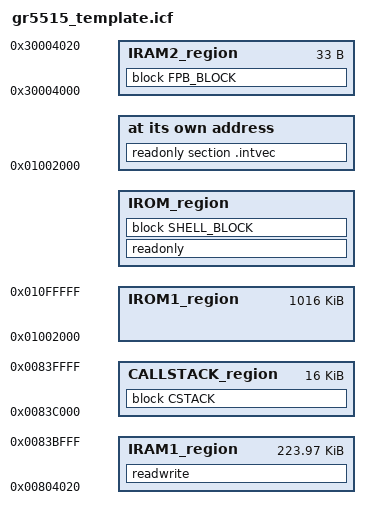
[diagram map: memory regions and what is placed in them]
/*###ICF### Section handled by ICF editor, don't touch! ****/
/*-Editor annotation file-*/
/* IcfEditorFile="$TOOLKIT_DIR$\config\ide\IcfEditor\cortex_v1_4.xml" */
/*-Specials-*/
define symbol __ICFEDIT_intvec_start__ = 0x01002000;
/*-Memory Regions-*/
define symbol __ICFEDIT_region_IROM1_start__ = 0x01002000;
define symbol __ICFEDIT_region_IROM1_end__   = 0x010FFFFF;
define symbol __ICFEDIT_region_IRAM1_start__ = 0x00804020;
define symbol __ICFEDIT_region_IRAM1_end__   = 0x0083BFFF;
define symbol __ICFEDIT_region_IRAM2_start__ = 0x30004000;
define symbol __ICFEDIT_region_IRAM2_end__   = 0x30004020;
define symbol __ICFEDIT_region_CALLSTACK_start__ = 0x0083C000;
define symbol __ICFEDIT_region_CALLSTACK_end__   = 0x0083FFFF;

/*-Sizes-*/
define symbol __ICFEDIT_size_cstack__     = 0x4000;
define symbol __ICFEDIT_size_proc_stack__ = 0x0;
define symbol __ICFEDIT_size_heap__       = 0x200;
/**** End of ICF editor section. ###ICF###*/

define memory mem with size = 4G;
define symbol use_IROM1 = (__ICFEDIT_region_IROM1_start__ != 0x0 || __ICFEDIT_region_IROM1_end__ != 0x0);
define symbol use_IRAM1 = (__ICFEDIT_region_IRAM1_start__ != 0x0 || __ICFEDIT_region_IRAM1_end__ != 0x0);
define symbol use_IRAM2 = (__ICFEDIT_region_IRAM2_start__ != 0x0 || __ICFEDIT_region_IRAM2_end__ != 0x0);


define region IROM1_region = mem:[from __ICFEDIT_region_IROM1_start__ to __ICFEDIT_region_IROM1_end__];

define region IROM_region = IROM1_region ;

define region IRAM1_region = mem:[from __ICFEDIT_region_IRAM1_start__ to __ICFEDIT_region_IRAM1_end__];

define region IRAM2_region = mem:[from __ICFEDIT_region_IRAM2_start__ to __ICFEDIT_region_IRAM2_end__];

define region CALLSTACK_region = mem:[from __ICFEDIT_region_CALLSTACK_start__ to __ICFEDIT_region_CALLSTACK_end__];

define region IRAM_region = IRAM1_region | IRAM2_region;

do not initialize  { section .noinit };
initialize by copy { readwrite  };
if (isdefinedsymbol(__USE_DLIB_PERTHREAD))
{
  // Required in a multi-threaded application
  initialize by copy with packing = none { section __DLIB_PERTHREAD };
}

place at address mem:__ICFEDIT_intvec_start__ { readonly section .intvec };

if (!isempty(IROM_region))
{
  define block SHELL_BLOCK  with alignment = 32, size = 0x2000 { section oshell };
  place in IROM_region  { readonly , block SHELL_BLOCK};
}

if (!isempty(IRAM_region))
{ 
  define block FPB_BLOCK  with alignment = 32, size = 0x20 { section FPB };
  define block CSTACK     with alignment = 8,  size=__ICFEDIT_size_cstack__{ };

  place in IRAM1_region  { readwrite };
  place in IRAM2_region  { block FPB_BLOCK };
  place in CALLSTACK_region  { block CSTACK};
}
